# f28e12x_analog_subsys_regs register map
Vendor: Texas Instruments
Peripheral module from a debugger description file (folder C2000).
Address unit: 16 bits
Registers are 32-bit, read-write, no defined reset value unless marked. A register's access mark holds for its fields unless they carry their own. Offsets are as the file gives them; lines under a group give offsets from that group; [hi:lo] are bit positions; {n}, {i} and the like mark numbered series; 'fields as' and 'values as' point back to an identical list; <NAME> marks a mode.

## ANALOG_SUBSYS_REGS — ANALOG SUBSYS Registers
0x2A EXTROSCCSR1 ro — ExtR Oscillator Status Register
  [31:24] OSCSTATUS — Running status of ExtR.
0x3A REFCONFIGA — Config register for analog reference A.
  [20] CONFIG8 — Analog reference mode select
0x56 INTERNALTESTCTL — INTERNALTEST Node Control Register
  [5:0] TESTSEL — Test Select
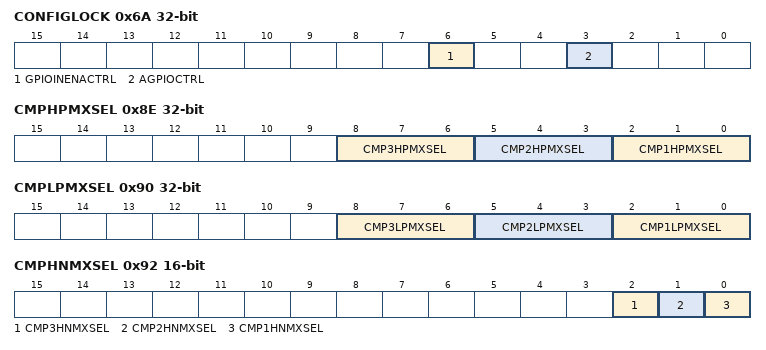
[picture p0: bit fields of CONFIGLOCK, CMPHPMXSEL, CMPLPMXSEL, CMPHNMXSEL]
0x6A CONFIGLOCK — Lock Register for all the config registers.
  [6] GPIOINENACTRL — Locks all GPIOINENACTRL Register
  [3] AGPIOCTRL — Locks all AGPIOCTRL Register
0x6C TSNSCTL 16-bit — Temperature Sensor Control Register
  [0] ENABLE — Temperature Sensor Enable
0x74 ANAREFCTL 16-bit — Analog Reference Control Register. This register is not configurable for 32QFN package
  [8] ANAREF2P5SEL — Analog Reference Select
0x7C VMONCTL 16-bit — Voltage Monitor Control Register
  [8] BORLVMONDIS — Disable BORL(ow) feature on VDDIO
0x8E CMPHPMXSEL — Bits to select one of the many sources on CompHP inputs. Refer to Pimux diagram for details.
  [8:6] CMP3HPMXSEL — CMP3HPMXSEL bits
  [5:3] CMP2HPMXSEL — CMP2HPMXSEL bits
  [2:0] CMP1HPMXSEL — CMP1HPMXSEL bits
0x90 CMPLPMXSEL — Bits to select one of the many sources on CompLP inputs. Refer to Pimux diagram for details.
  [8:6] CMP3LPMXSEL — CMP3LPMXSEL bits
  [5:3] CMP2LPMXSEL — CMP2LPMXSEL bits
  [2:0] CMP1LPMXSEL — CMP1LPMXSEL bits
0x92 CMPHNMXSEL 16-bit — Bits to select one of the many sources on CompHN inputs. Refer to Pimux diagram for details.
  [2] CMP3HNMXSEL — CMP3HNMXSEL bits
  [1] CMP2HNMXSEL — CMP2HNMXSEL bits
  [0] CMP1HNMXSEL — CMP1HNMXSEL bits
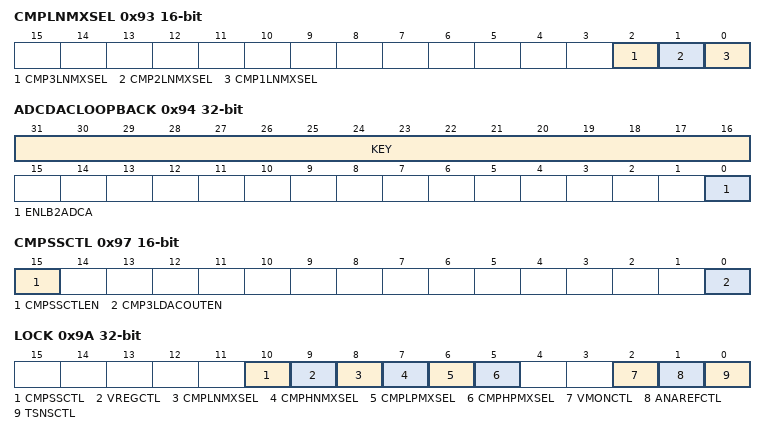
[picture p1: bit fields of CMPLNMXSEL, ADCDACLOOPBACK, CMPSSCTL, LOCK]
0x93 CMPLNMXSEL 16-bit — Bits to select one of the many sources on CompLN inputs. Refer to Pimux diagram for details.
  [2] CMP3LNMXSEL — CMP3LNMXSEL bits
  [1] CMP2LNMXSEL — CMP2LNMXSEL bits
  [0] CMP1LNMXSEL — CMP1LNMXSEL bits
0x94 ADCDACLOOPBACK — Enabble loopback from DAC to ADCs
  [31:16] KEY — Key to enable writes
  [0] ENLB2ADCA — Enable CMPSS.DAC loopback to ADCA
0x97 CMPSSCTL 16-bit — CMPSS Control Register
  [15] CMPSSCTLEN — Enable the CMPSSCTL Register
  [0] CMP3LDACOUTEN — Enable general purpose DAC functionality for CMPSS3.COMPDACL
0x9A LOCK
  [10] CMPSSCTL — CMPSSCTL Register lock bit
  [9] VREGCTL — VREGCTL Register lock bit
  [8] CMPLNMXSEL — CMPLNMXSEL Register lock bit
  [7] CMPHNMXSEL — CMPHNMXSEL Register lock bit
  [6] CMPLPMXSEL — CMPLPMXSEL Register lock bit
  [5] CMPHPMXSEL — CMPHPMXSEL Register lock bit
  [2] VMONCTL — VMONCTL Register lock bit
  [1] ANAREFCTL — ANAREFCTL Register lock bit
  [0] TSNSCTL — TSNSCTL Register lock bit
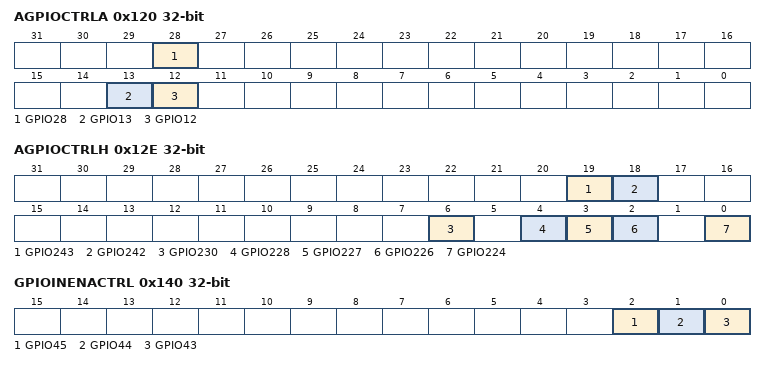
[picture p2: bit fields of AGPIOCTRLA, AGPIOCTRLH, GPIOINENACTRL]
0x120 AGPIOCTRLA — AGPIO Control Register
  [28] GPIO28 — AGPIOCTRL for GPIO28
  [13] GPIO13 — AGPIOCTRL for GPIO13
  [12] GPIO12 — AGPIOCTRL for GPIO12
0x12E AGPIOCTRLH — AGPIO Control Register
  [19] GPIO243 — AGPIOCTRL for GPIO243
  [18] GPIO242 — AGPIOCTRL for GPIO242
  [6] GPIO230 — AGPIOCTRL for GPIO230
  [4] GPIO228 — AGPIOCTRL for GPIO228
  [3] GPIO227 — AGPIOCTRL for GPIO227
  [2] GPIO226 — AGPIOCTRL for GPIO226
  [0] GPIO224 — AGPIOCTRL for GPIO224
0x140 GPIOINENACTRL — GPIOINENACTRL Control Register
  [2] GPIO45 — Input Buffer Control for GPIO45
  [1] GPIO44 — Input Buffer Control for GPIO44
  [0] GPIO43 — Input Buffer Control for GPIO43
